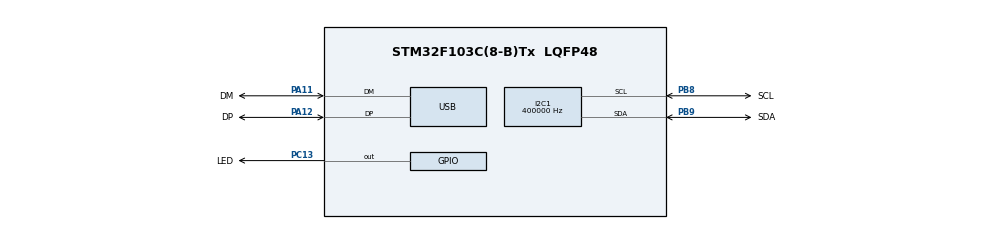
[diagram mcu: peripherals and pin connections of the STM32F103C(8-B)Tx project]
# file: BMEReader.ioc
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I2C1.ClockSpeed=400000
I2C1.DutyCycle=I2C_DUTYCYCLE_2
I2C1.I2C_Mode=I2C_Fast
Mcu.Family=STM32F1
Mcu.Name=STM32F103C(8-B)Tx
Mcu.Package=LQFP48
NVIC.PriorityGroup=NVIC_PRIORITYGROUP_4
NVIC.USB_LP_CAN1_RX0_IRQn=true\:1\:0\:true\:false\:true\:false\:true
PA11.GPIO_Label=DM
PA11.Mode=Device
PA11.Signal=USB_DM
PA12.GPIO_Label=DP
PA12.Mode=Device
PA12.Signal=USB_DP
PA13.GPIO_Label=SWDIO
PA13.Mode=Serial_Wire
PA13.Signal=SYS_JTMS-SWDIO
PA14.GPIO_Label=SWCLK
PA14.Mode=Serial_Wire
PA14.Signal=SYS_JTCK-SWCLK
PB8.GPIO_Label=SCL
PB8.GPIO_Speed=GPIO_SPEED_FREQ_LOW
PB8.Mode=I2C
PB8.Signal=I2C1_SCL
PB9.GPIO_Label=SDA
PB9.GPIO_Speed=GPIO_SPEED_FREQ_LOW
PB9.Mode=I2C
PB9.Signal=I2C1_SDA
PC13-TAMPER-RTC.GPIO_Label=LED
PC13-TAMPER-RTC.Signal=GPIO_Output
PD0-OSC_IN.GPIO_Label=OSC_IN
PD0-OSC_IN.Mode=HSE-External-Oscillator
PD0-OSC_IN.Signal=RCC_OSC_IN
PD1-OSC_OUT.GPIO_Label=OSC_OUT
PD1-OSC_OUT.Mode=HSE-External-Oscillator
PD1-OSC_OUT.Signal=RCC_OSC_OUT
ProjectManager.HeapSize=0x100
ProjectManager.StackSize=0x200
ProjectManager.TargetToolchain=STM32CubeIDE
RCC.AHBFreq_Value=72000000
RCC.APB1CLKDivider=RCC_HCLK_DIV2
RCC.APB1Freq_Value=36000000
RCC.APB1TimFreq_Value=72000000
RCC.APB2Freq_Value=72000000
RCC.APB2TimFreq_Value=72000000
RCC.HCLKFreq_Value=72000000
RCC.PLLMUL=RCC_PLL_MUL9
RCC.SYSCLKFreq_VALUE=72000000
RCC.SYSCLKSource=RCC_SYSCLKSOURCE_PLLCLK
RCC.USBFreq_Value=48000000
RCC.USBPrescaler=RCC_USBCLKSOURCE_PLL_DIV1_5
USB_DEVICE.APP_RX_DATA_SIZE=64
USB_DEVICE.APP_TX_DATA_SIZE=64
USB_DEVICE.CLASS_NAME_FS=CDC
USB_DEVICE.PID_CDC_FS=0x5740
USB_DEVICE.PRODUCT_STRING_CDC_FS=STM32 Virtual ComPort
USB_DEVICE.USBD_MAX_STR_DESC_SIZ=256
USB_DEVICE.VID=0x483
USB_DEVICE.VirtualMode=Cdc
USB_DEVICE.VirtualModeFS=Cdc_FS
VP_USB_DEVICE_VS_USB_DEVICE_CDC_FS.Mode=CDC_FS
board=custom

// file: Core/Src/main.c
/* USER CODE BEGIN Header */
/**
  ******************************************************************************
  * @file           : main.c
  * @brief          : Main program body
  ******************************************************************************
  * @attention
  *
  * <h2><center>&copy; Copyright (c) 2021 STMicroelectronics.
  * All rights reserved.</center></h2>
  *
  * This software component is licensed by ST under Ultimate Liberty license
  * SLA0044, the "License"; You may not use this file except in compliance with
  * the License. You may obtain a copy of the License at:
  *                             www.st.com/SLA0044
  *
  ******************************************************************************
  */
/* USER CODE END Header */
#include "main.h"
#include "usb_device.h"

/* USER CODE BEGIN Includes */
#include "project.h"
/* USER CODE END Includes */

/* USER CODE BEGIN PM */
#pragma ide diagnostic ignored "EndlessLoop"
/* USER CODE END PM */

void SystemClock_Config(void);

int main(void)
{

  /* MCU Configuration--------------------------------------------------------*/

  /* Reset of all peripherals, Initializes the Flash interface and the Systick. */
  HAL_Init();

  /* Configure the system clock */
  SystemClock_Config();

  /* USER CODE BEGIN SysInit */
  Project_PreInit();
  /* USER CODE END SysInit */

  /* Initialize all configured peripherals */
  MX_GPIO_Init();
  MX_I2C1_Init();
  MX_USB_DEVICE_Init();
  /* USER CODE BEGIN 2 */

  Project_PostInit();
  /* USER CODE END 2 */

  /* Infinite loop */
  /* USER CODE BEGIN WHILE */
  while (1)
  {
    Project_Loop();
    /* USER CODE END WHILE */

  }
}

void SystemClock_Config(void)
{
  LL_FLASH_SetLatency(LL_FLASH_LATENCY_2);
  while(LL_FLASH_GetLatency()!= LL_FLASH_LATENCY_2)
  {
  }
  LL_RCC_HSE_Enable();

   /* Wait till HSE is ready */
  while(LL_RCC_HSE_IsReady() != 1)
  {

  }
  LL_RCC_PLL_ConfigDomain_SYS(LL_RCC_PLLSOURCE_HSE_DIV_1, LL_RCC_PLL_MUL_9);
  LL_RCC_PLL_Enable();

   /* Wait till PLL is ready */
  while(LL_RCC_PLL_IsReady() != 1)
  {

  }
  LL_RCC_SetAHBPrescaler(LL_RCC_SYSCLK_DIV_1);
  LL_RCC_SetAPB1Prescaler(LL_RCC_APB1_DIV_2);
  LL_RCC_SetAPB2Prescaler(LL_RCC_APB2_DIV_1);
  LL_RCC_SetSysClkSource(LL_RCC_SYS_CLKSOURCE_PLL);

   /* Wait till System clock is ready */
  while(LL_RCC_GetSysClkSource() != LL_RCC_SYS_CLKSOURCE_STATUS_PLL)
  {

  }
  LL_SetSystemCoreClock(72000000);

   /* Update the time base */
  if (HAL_InitTick (TICK_INT_PRIORITY) != HAL_OK)
  {
    Error_Handler();
  }
  LL_RCC_SetUSBClockSource(LL_RCC_USB_CLKSOURCE_PLL_DIV_1_5);
}

void MX_I2C1_Init(void)
{

  LL_I2C_InitTypeDef I2C_InitStruct = {0};

  LL_GPIO_InitTypeDef GPIO_InitStruct = {0};

  LL_APB2_GRP1_EnableClock(LL_APB2_GRP1_PERIPH_GPIOB);
  /**I2C1 GPIO Configuration
  PB8   ------> I2C1_SCL
  PB9   ------> I2C1_SDA
  */
  GPIO_InitStruct.Pin = SCL_Pin|SDA_Pin;
  GPIO_InitStruct.Mode = LL_GPIO_MODE_ALTERNATE;
  GPIO_InitStruct.Speed = LL_GPIO_SPEED_FREQ_LOW;
  GPIO_InitStruct.OutputType = LL_GPIO_OUTPUT_OPENDRAIN;
  LL_GPIO_Init(GPIOB, &GPIO_InitStruct);

  LL_GPIO_AF_EnableRemap_I2C1();

  /* Peripheral clock enable */
  LL_APB1_GRP1_EnableClock(LL_APB1_GRP1_PERIPH_I2C1);

  /** I2C Initialization
  */
  LL_I2C_DisableOwnAddress2(I2C1);
  LL_I2C_DisableGeneralCall(I2C1);
  LL_I2C_EnableClockStretching(I2C1);
  I2C_InitStruct.PeripheralMode = LL_I2C_MODE_I2C;
  I2C_InitStruct.ClockSpeed = 400000;
  I2C_InitStruct.DutyCycle = LL_I2C_DUTYCYCLE_2;
  I2C_InitStruct.OwnAddress1 = 0;
  I2C_InitStruct.TypeAcknowledge = LL_I2C_ACK;
  I2C_InitStruct.OwnAddrSize = LL_I2C_OWNADDRESS1_7BIT;
  LL_I2C_Init(I2C1, &I2C_InitStruct);
  LL_I2C_SetOwnAddress2(I2C1, 0);

}

void MX_GPIO_Init(void)
{
  LL_GPIO_InitTypeDef GPIO_InitStruct = {0};

  /* GPIO Ports Clock Enable */
  LL_APB2_GRP1_EnableClock(LL_APB2_GRP1_PERIPH_GPIOC);
  LL_APB2_GRP1_EnableClock(LL_APB2_GRP1_PERIPH_GPIOD);
  LL_APB2_GRP1_EnableClock(LL_APB2_GRP1_PERIPH_GPIOA);
  LL_APB2_GRP1_EnableClock(LL_APB2_GRP1_PERIPH_GPIOB);

  /**/
  LL_GPIO_ResetOutputPin(LED_GPIO_Port, LED_Pin);

  /**/
  GPIO_InitStruct.Pin = LED_Pin;
  GPIO_InitStruct.Mode = LL_GPIO_MODE_OUTPUT;
  GPIO_InitStruct.Speed = LL_GPIO_SPEED_FREQ_LOW;
  GPIO_InitStruct.OutputType = LL_GPIO_OUTPUT_PUSHPULL;
  LL_GPIO_Init(LED_GPIO_Port, &GPIO_InitStruct);

}

void Error_Handler(void)
{
  /* USER CODE BEGIN Error_Handler_Debug */
  /* User can add his own implementation to report the HAL error return state */
  /*
  __disable_irq();
  while (1)
  {
  }
   */
  /* USER CODE END Error_Handler_Debug */
}

/************************ (C) COPYRIGHT STMicroelectronics *****END OF FILE****/
